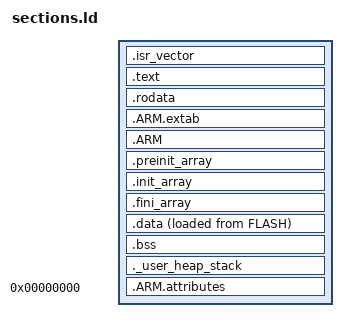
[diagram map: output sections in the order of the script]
/*
 * Default linker script for Cortex-M (it includes specifics for STM32F[34]xx).
 * 
 * To make use of the multi-region initialisations, define
 * OS_INCLUDE_STARTUP_INIT_MULTIPLE_RAM_SECTIONS for the _startup.c file.
 */

/*
 * The '__stack' definition is required by crt0, do not remove it.
 */
__stack = ORIGIN(RAM) + LENGTH(RAM);

_estack = __stack; 	/* STM specific definition */

/*
 * Default stack sizes.
 * These are used by the startup in order to allocate stacks 
 * for the different modes.
 */

__Main_Stack_Size = 1024 ;

PROVIDE ( _Main_Stack_Size = __Main_Stack_Size ) ;

__Main_Stack_Limit = __stack  - __Main_Stack_Size ;

/* "PROVIDE" allows to easily override these values from an 
 * object file or the command line. */
PROVIDE ( _Main_Stack_Limit = __Main_Stack_Limit ) ;

/*
 * There will be a link error if there is not this amount of 
 * RAM free at the end. 
 */
_Min_Heap_Size = 0x200;
_Min_Stack_Size = 0x400 ;

/*
 * Default heap definitions.
 * The heap start immediately after the last statically allocated 
 * .sbss/.noinit section, and extends up to the main stack limit.
 */
PROVIDE ( _Heap_Begin = _end_noinit ) ;
PROVIDE ( _Heap_Limit = __stack - __Main_Stack_Size ) ;

/* 
 * The entry point is informative, for debuggers and simulators,
 * since the Cortex-M vector points to it anyway.
 */
ENTRY(_start)


/* Sections Definitions */

SECTIONS
{
  /* The startup code goes first into FLASH */
  .isr_vector :
  {
    . = ALIGN(4);
    KEEP(*(.isr_vector)) /* Startup code */
    . = ALIGN(4);
  } >FLASH

  /* The program code and other data goes into FLASH */
  .text :
  {
    . = ALIGN(4);
    *(.text)           /* .text sections (code) */
    *(.text*)          /* .text* sections (code) */
    *(.glue_7)         /* glue arm to thumb code */
    *(.glue_7t)        /* glue thumb to arm code */
    *(.eh_frame)

    KEEP (*(.init))
    KEEP (*(.fini))

    . = ALIGN(4);
    _etext = .;        /* define a global symbols at end of code */
  } >FLASH

  /* Constant data goes into FLASH */
  .rodata :
  {
    . = ALIGN(4);
    *(.rodata)         /* .rodata sections (constants, strings, etc.) */
    *(.rodata*)        /* .rodata* sections (constants, strings, etc.) */
    . = ALIGN(4);
  } >FLASH

  .ARM.extab   : { *(.ARM.extab* .gnu.linkonce.armextab.*) } >FLASH
  .ARM : {
    __exidx_start = .;
    *(.ARM.exidx*)
    __exidx_end = .;
  } >FLASH

  .preinit_array     :
  {
    PROVIDE_HIDDEN (__preinit_array_start = .);
    KEEP (*(.preinit_array*))
    PROVIDE_HIDDEN (__preinit_array_end = .);
  } >FLASH
  .init_array :
  {
    PROVIDE_HIDDEN (__init_array_start = .);
    KEEP (*(SORT(.init_array.*)))
    KEEP (*(.init_array*))
    PROVIDE_HIDDEN (__init_array_end = .);
  } >FLASH
  .fini_array :
  {
    PROVIDE_HIDDEN (__fini_array_start = .);
    KEEP (*(SORT(.fini_array.*)))
    KEEP (*(.fini_array*))
    PROVIDE_HIDDEN (__fini_array_end = .);
  } >FLASH

  /* used by the startup to initialize data */
  _sidata = LOADADDR(.data);

  /* Initialized data sections goes into RAM, load LMA copy after code */
  .data :
  {
    . = ALIGN(4);
    _sdata = .;        /* create a global symbol at data start */
    *(.data)           /* .data sections */
    *(.data*)          /* .data* sections */

    . = ALIGN(4);
    _edata = .;        /* define a global symbol at data end */
  } >RAM AT> FLASH


  /* Uninitialized data section */
  . = ALIGN(4);
  .bss :
  {
    /* This is used by the startup in order to initialize the .bss secion */
    _sbss = .;         /* define a global symbol at bss start */
    __bss_start__ = _sbss;
    *(.bss)
    *(.bss*)
    *(COMMON)

    . = ALIGN(4);
    _ebss = .;         /* define a global symbol at bss end */
    __bss_end__ = _ebss;
  } >RAM

  /* User_heap_stack section, used to check that there is enough RAM left */
  ._user_heap_stack :
  {
    . = ALIGN(8);
    PROVIDE ( end = . );
    PROVIDE ( _end = . );
    . = . + _Min_Heap_Size;
    . = . + _Min_Stack_Size;
    . = ALIGN(8);
  } >RAM



  /* Remove information from the standard libraries */
  /DISCARD/ :
  {
    libc.a ( * )
    libm.a ( * )
    libgcc.a ( * )
  }

  .ARM.attributes 0 : { *(.ARM.attributes) }
}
